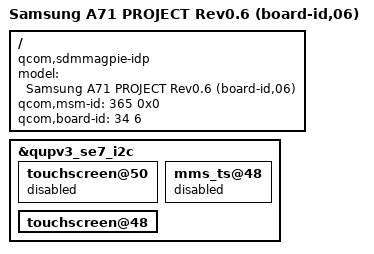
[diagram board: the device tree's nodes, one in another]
/* Copyright (c) 2019, The Linux Foundation. All rights reserved. 
* 
* This program is free software; you can redistribute it and/or modify 
* it under the terms of the GNU General Public License version 2 and 
* only version 2 as published by the Free Software Foundation. 
* 
* This program is distributed in the hope that it will be useful, 
* but WITHOUT ANY WARRANTY; without even the implied warranty of 
* MERCHANTABILITY or FITNESS FOR A PARTICULAR PURPOSE.  See the 
* GNU General Public License for more details. 
*/ 
 
/dts-v1/; 
/plugin/; 
 
#include "common/sm7150-sec-common.dtsi" 
#include "a71/sm7150-sec-a71-eur-ldu-r06.dtsi" 
/* FIXME : strongly recommend to move it to sm7150-sec-a71-eur-r0n.dtsi */
#include "drivers/sm7150-sec-a71-display-r04.dtsi"
#include "drivers/sm7150-sec-a71-battery-r06.dtsi"
#include "drivers/sm7150-sec-a71-eif-r06.dtsi"

 
/ { 
	model = "Samsung A71 PROJECT Rev0.6 (board-id,06)"; 
	compatible = "qcom,sdmmagpie-idp", "qcom,sdmmagpie", "qcom,idp"; 
	qcom,msm-id = <365 0x0>; 
	qcom,board-id = <34 6>; 
}; 
 
&qupv3_se7_i2c { 
	touchscreen@50 {
		status = "disabled";
	}; 
	mms_ts@48 {
		status = "disabled";
	};
	touchscreen@48 {
		status = "ok";
	};
}; 
